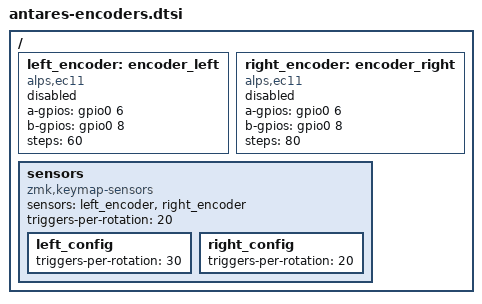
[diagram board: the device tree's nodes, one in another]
/ {
	left_encoder: encoder_left {
		compatible = "alps,ec11";
		a-gpios = <&gpio0 6 (GPIO_ACTIVE_HIGH | GPIO_PULL_UP)>;
		b-gpios = <&gpio0 8 (GPIO_ACTIVE_HIGH | GPIO_PULL_UP)>;
		steps = <60>; // 15 pulses per rotation, four signal changes per pulse
		status = "disabled";
	};

	right_encoder: encoder_right {
		compatible = "alps,ec11";
		a-gpios = <&gpio0 6 (GPIO_ACTIVE_HIGH | GPIO_PULL_UP)>;
		b-gpios = <&gpio0 8 (GPIO_ACTIVE_HIGH | GPIO_PULL_UP)>;
		steps = <80>;
		status = "disabled";
	};

  // https://zmk.dev/docs/config/encoders#keymap-sensor-config
	sensors {
		compatible = "zmk,keymap-sensors";
		sensors = <&left_encoder &right_encoder>;
		triggers-per-rotation = <20>;

		left_config {
			triggers-per-rotation = <30>; // one volume tap per detent
		};

		right_config {
			triggers-per-rotation = <20>;
		};
	};
};
